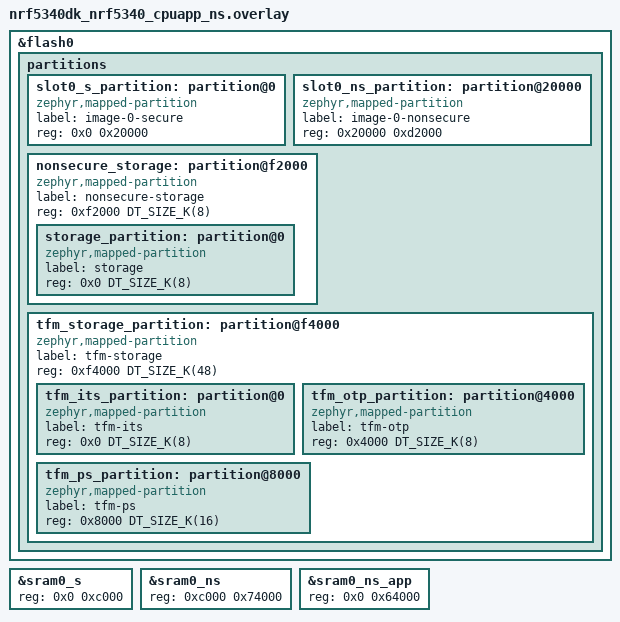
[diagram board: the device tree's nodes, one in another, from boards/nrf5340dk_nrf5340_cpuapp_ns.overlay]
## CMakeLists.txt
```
#
# Copyright (c) 2018 Nordic Semiconductor
#
# SPDX-License-Identifier: LicenseRef-Nordic-5-Clause
#

cmake_minimum_required(VERSION 3.20.0)

find_package(Zephyr REQUIRED HINTS $ENV{ZEPHYR_BASE})
project(NONE)

# NORDIC SDK APP START
if(CONFIG_SOC_NRF9251_CPUAPP)
target_sources(app PRIVATE src/main_cpuapp_idle.c)
else()
target_sources(app PRIVATE src/main.c src/ndef_file_m.c)
endif()
# NORDIC SDK APP END
```

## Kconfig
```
#
# Copyright (c) 2025 Nordic Semiconductor
#
# SPDX-License-Identifier: LicenseRef-Nordic-5-Clause
#

source "Kconfig.zephyr"

config NDEF_FILE_STORAGE_RAM
	bool "Keep NDEF file in RAM only (no flash persistence)"
	default y if RISCV_CORE_NORDIC_VPR
	help
	  Nordic VPR cores (for example nRF9251 CPUPPR/CPUFLPR) cannot use the MRAM
	  flash driver (see SOC_FLASH_NRF_MRAM). Enable this to store the NDEF
	  file in RAM, which is lost on reset.

config ZMS
	select CRC
	default y if (SOC_FLASH_NRF_RRAM || SOC_FLASH_NRF_MRAM) && !NDEF_FILE_STORAGE_RAM

config NVS
	default y if !(SOC_FLASH_NRF_RRAM || SOC_FLASH_NRF_MRAM) && !NDEF_FILE_STORAGE_RAM
```

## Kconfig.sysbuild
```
#
# Copyright (c) 2026 Nordic Semiconductor ASA
#
# SPDX-License-Identifier: LicenseRef-Nordic-5-Clause
#

choice NETCORE
	default NETCORE_EMPTY

endchoice

if SUPPORT_PPRCORE

choice PPRCORE
	default PPRCORE_REMOTE

config PPRCORE_REMOTE
	bool "Remote image (NFC sample on CPUPPR)"

endchoice

config PPRCORE_IMAGE_NAME
	default "remote_ppr" if PPRCORE_REMOTE

config PPRCORE_IMAGE_PATH
	default "$(APP_DIR)/remote" if PPRCORE_REMOTE

endif # SUPPORT_PPRCORE

source "share/sysbuild/Kconfig"
```

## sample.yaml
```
sample:
  description: NFC Writable NDEF Message sample
  name: NFC Writable NDEF Message
tests:
  sample.nfc.writable_ndef_msg:
    sysbuild: true
    build_only: true
    integration_platforms:
      - nrf52840dk/nrf52840
      - nrf5340dk/nrf5340/cpuapp
      - nrf5340dk/nrf5340/cpuapp/ns
      - nrf54h20dk/nrf54h20/cpuapp
      - nrf54l15dk/nrf54l05/cpuapp
      - nrf54l15dk/nrf54l10/cpuapp
      - nrf54l15dk/nrf54l15/cpuapp
      - nrf54lm20dk/nrf54lm20a/cpuapp
      - nrf54lm20dk/nrf54lm20b/cpuapp
      - nrf7120dk/nrf7120/cpuapp
    platform_allow:
      - nrf52840dk/nrf52840
      - nrf52dk/nrf52832
      - nrf5340dk/nrf5340/cpuapp
      - nrf5340dk/nrf5340/cpuapp/ns
      - nrf54h20dk/nrf54h20/cpuapp
      - nrf54l15dk/nrf54l05/cpuapp
      - nrf54l15dk/nrf54l10/cpuapp
      - nrf54l15dk/nrf54l15/cpuapp
      - nrf54lm20dk/nrf54lm20a/cpuapp
      - nrf54lm20dk/nrf54lm20b/cpuapp
      - nrf7120dk/nrf7120/cpuapp
    tags:
      - ci_build
      - sysbuild
      - ci_samples_nfc
  sample.nfc.writable_ndef_msg.llvm:
    toolchain_allow: llvm
    sysbuild: true
    build_only: true
    integration_platforms:
      - nrf54l15dk/nrf54l15/cpuapp
    platform_allow:
      - nrf54l15dk/nrf54l15/cpuapp
    tags:
      - ci_build
      - sysbuild
      - ci_samples_nfc
```

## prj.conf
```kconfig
#
# Copyright (c) 2019 Nordic Semiconductor ASA
#
# SPDX-License-Identifier: LicenseRef-Nordic-5-Clause
#
CONFIG_NCS_SAMPLES_DEFAULTS=y

CONFIG_NFC_T4T_NRFXLIB=y

CONFIG_NFC_NDEF=y
CONFIG_NFC_NDEF_MSG=y
CONFIG_NFC_NDEF_RECORD=y
CONFIG_NFC_NDEF_URI_REC=y
CONFIG_NFC_NDEF_URI_MSG=y

CONFIG_MPU_ALLOW_FLASH_WRITE=y
CONFIG_FLASH=y
CONFIG_FLASH_PAGE_LAYOUT=y
CONFIG_DK_LIBRARY=y
```

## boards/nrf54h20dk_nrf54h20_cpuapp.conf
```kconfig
#
# Copyright (c) 2024 Nordic Semiconductor ASA
#
# SPDX-License-Identifier: LicenseRef-Nordic-5-Clause
#

CONFIG_NVS=n
CONFIG_ZMS=y
```

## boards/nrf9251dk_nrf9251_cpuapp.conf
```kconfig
#
# Copyright (c) 2026 Nordic Semiconductor ASA
#
# SPDX-License-Identifier: LicenseRef-Nordic-5-Clause
#

# Disable NFC low latency IRQ
CONFIG_NFC_LOW_LATENCY_IRQ=n

# Application core stays idle
CONFIG_PM=y
CONFIG_PM_DEVICE=y
CONFIG_PM_DEVICE_RUNTIME=y
CONFIG_POWEROFF=y

CONFIG_NFC_T4T_NRFXLIB=n
CONFIG_NFC_NDEF=n
CONFIG_NFC_NDEF_MSG=n
CONFIG_NFC_NDEF_RECORD=n
CONFIG_NFC_NDEF_URI_REC=n
CONFIG_NFC_NDEF_URI_MSG=n

CONFIG_DK_LIBRARY=n
CONFIG_FLASH=n
CONFIG_FLASH_PAGE_LAYOUT=n
CONFIG_MPU_ALLOW_FLASH_WRITE=n

CONFIG_SERIAL=n
CONFIG_CONSOLE=n
CONFIG_UART_CONSOLE=n
CONFIG_PRINTK=n
CONFIG_LOG=n
CONFIG_BOOT_BANNER=n
CONFIG_NCS_BOOT_BANNER=n
```

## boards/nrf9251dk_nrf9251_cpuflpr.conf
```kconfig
#
# Copyright (c) 2026 Nordic Semiconductor ASA
#
# SPDX-License-Identifier: LicenseRef-Nordic-5-Clause
#

# Disable NFC low latency IRQ
CONFIG_NFC_LOW_LATENCY_IRQ=n

CONFIG_DK_LIBRARY=n

CONFIG_FLASH=n
CONFIG_FLASH_PAGE_LAYOUT=n
CONFIG_MPU_ALLOW_FLASH_WRITE=n

CONFIG_REBOOT=n
CONFIG_ASSERT=n
```

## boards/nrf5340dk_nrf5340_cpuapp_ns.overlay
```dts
/*
 * Copyright (c) 2026 Nordic Semiconductor ASA
 *
 * SPDX-License-Identifier: LicenseRef-Nordic-5-Clause
 */

/delete-node/ &boot_partition;
/delete-node/ &slot0_partition;
/delete-node/ &slot1_partition;
/delete-node/ &tfm_its_partition;
/delete-node/ &tfm_otp_partition;
/delete-node/ &tfm_ps_partition;
/delete-node/ &storage_partition;

&flash0 {
	partitions {
		slot0_s_partition: partition@0 {
			compatible = "zephyr,mapped-partition";
			label = "image-0-secure";
			reg = <0x0 0x20000>;
		};

		slot0_ns_partition: partition@20000 {
			compatible = "zephyr,mapped-partition";
			label = "image-0-nonsecure";
			reg = <0x20000 0xd2000>;
		};

		nonsecure_storage: partition@f2000 {
			compatible = "zephyr,mapped-partition";
			label = "nonsecure-storage";
			reg = <0xf2000 DT_SIZE_K(8)>;
			ranges = <0x0 0xf2000 DT_SIZE_K(8)>;
			#address-cells = <1>;
			#size-cells = <1>;

			storage_partition: partition@0 {
				compatible = "zephyr,mapped-partition";
				label = "storage";
				reg = <0x0 DT_SIZE_K(8)>;
			};
		};

		tfm_storage_partition: partition@f4000 {
			compatible = "zephyr,mapped-partition";
			label = "tfm-storage";
			reg = <0xf4000 DT_SIZE_K(48)>;
			ranges = <0x0 0xf4000 DT_SIZE_K(48)>;
			#address-cells = <1>;
			#size-cells = <1>;

			tfm_its_partition: partition@0 {
				compatible = "zephyr,mapped-partition";
				label = "tfm-its";
				reg = <0x0 DT_SIZE_K(8)>;
			};

			tfm_otp_partition: partition@4000 {
				compatible = "zephyr,mapped-partition";
				label = "tfm-otp";
				reg = <0x4000 DT_SIZE_K(8)>;
			};

			tfm_ps_partition: partition@8000 {
				compatible = "zephyr,mapped-partition";
				label = "tfm-ps";
				reg = <0x8000 DT_SIZE_K(16)>;
			};
		};
	};
};

&sram0_s {
	reg = <0x0 0xc000>;
};

&sram0_ns {
	reg = <0xc000 0x74000>;
	ranges = <0x0 0xc000 0x74000>;
};

&sram0_ns_app {
	reg = <0x0 0x64000>;
};

/*
 * This layout redefines the flash partition map, dropping partitions that the
 * upstream nordic-tz-secure/-nonsecure descriptors reference. Remove the
 * descriptors so they do not hold dangling phandles (restores the behaviour
 * from before the descriptors were introduced).
 */
/ {
	/delete-node/ nordic-tz-secure;
	/delete-node/ nordic-tz-nonsecure;
};
```

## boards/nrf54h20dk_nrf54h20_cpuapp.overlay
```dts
/*
 * Copyright (c) 2024 Nordic Semiconductor ASA
 *
 * SPDX-License-Identifier: LicenseRef-Nordic-5-Clause
 */

&nfct {
	status = "okay";
	memory-regions = <&cpuapp_dma_region>;
};

&timer137 {
	status = "okay";
};
```

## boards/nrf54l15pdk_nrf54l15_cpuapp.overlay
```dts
/*
 * Copyright (c) 2024 Nordic Semiconductor ASA
 *
 * SPDX-License-Identifier: LicenseRef-Nordic-5-Clause
 */

/*
 * The sample does not use Buttons 3 and 4.
 * Buttons 3 and 4 in PDK are connected to the GPIO port, which does not support interrupts.
 */

 / {
	aliases {
		/delete-property/ sw2;
		/delete-property/ sw3;
	};
	buttons {
		/delete-node/ button_2;
		/delete-node/ button_3;
	};
};
```

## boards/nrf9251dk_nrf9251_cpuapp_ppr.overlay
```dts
/*
 * Copyright (c) 2026 Nordic Semiconductor ASA
 *
 * SPDX-License-Identifier: LicenseRef-Nordic-5-Clause
 */

&gpiote130 {
	status = "okay";
};

&cpuppr_vpr {
	status = "okay";
};

&uart132 {
	status = "reserved";
	interrupt-parent = <&cpuppr_clic>;
};

&nfct {
	status = "reserved";
	interrupt-parent = <&cpuppr_clic>;
};

&hfxo {
	status = "reserved";
};
```

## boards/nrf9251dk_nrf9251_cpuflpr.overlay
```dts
/*
 * Copyright (c) 2026 Nordic Semiconductor ASA
 *
 * SPDX-License-Identifier: LicenseRef-Nordic-5-Clause
 */

&nfct {
	status = "okay";
	interrupt-parent = <&cpuflpr_clic>;
};

&hfxo {
	status = "okay";
};

&gpio0 {
	status = "okay";
};

&gpio2 {
	status = "okay";
};

&gpiote130 {
	status = "okay";
};
```

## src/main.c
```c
/*
 * Copyright (c) 2018 Nordic Semiconductor ASA
 *
 * SPDX-License-Identifier: LicenseRef-Nordic-5-Clause
 */

/** @file
 *
 * @defgroup nfc_writable_ndef_msg_example_main main.c
 * @{
 * @ingroup nfc_writable_ndef_msg_example
 * @brief The application main file of NFC writable NDEF message example.
 *
 */

#include <zephyr/kernel.h>
#if defined(CONFIG_REBOOT)
#include <zephyr/sys/reboot.h>
#endif /* CONFIG_REBOOT */

#include "ndef_file_m.h"

#include <nfc_t4t_lib.h>
#include <nfc/ndef/msg.h>
#include <nfc/t4t/ndef_file.h>

#if defined(CONFIG_DK_LIBRARY)
#include <dk_buttons_and_leds.h>

#define NFC_FIELD_LED		DK_LED1
#define NFC_WRITE_LED		DK_LED2
#define NFC_READ_LED		DK_LED4

#define NDEF_RESTORE_BTN_MSK	DK_BTN1_MSK
#endif /* CONFIG_DK_LIBRARY */

static uint8_t ndef_msg_buf[CONFIG_NDEF_FILE_SIZE]; /**< Buffer for NDEF file. */

enum {
	FLASH_WRITE_FINISHED,
	FLASH_BUF_PREP_STARTED,
	FLASH_BUF_PREP_FINISHED,
	FLASH_WRITE_STARTED,
};

static atomic_t op_flags;

static uint8_t flash_buf[CONFIG_NDEF_FILE_SIZE]; /**< Buffer for storage update. */
static uint8_t flash_buf_len; /**< Length of the storage buffer. */

static K_SEM_DEFINE(nfc_write_sem, 0, 1);

static void flash_buffer_prepare(size_t data_length)
{
	if (atomic_cas(&op_flags, FLASH_WRITE_FINISHED,
			FLASH_BUF_PREP_STARTED)) {
		flash_buf_len = data_length + NFC_NDEF_FILE_NLEN_FIELD_SIZE;
		memcpy(flash_buf, ndef_msg_buf, sizeof(flash_buf));

		atomic_set(&op_flags, FLASH_BUF_PREP_FINISHED);
		k_sem_give(&nfc_write_sem);
	} else {
		printk("Flash update pending. Discarding new data...\n");
	}

}

/**
 * @brief Callback function for handling NFC events.
 */
static void nfc_callback(void *context,
			 nfc_t4t_event_t event,
			 const uint8_t *data,
			 size_t data_length,
			 uint32_t flags)
{
	ARG_UNUSED(context);
	ARG_UNUSED(data);
	ARG_UNUSED(flags);

	switch (event) {
	case NFC_T4T_EVENT_FIELD_ON:
#if defined(CONFIG_DK_LIBRARY)
		dk_set_led_on(NFC_FIELD_LED);
#endif /* CONFIG_DK_LIBRARY */
		break;

	case NFC_T4T_EVENT_FIELD_OFF:
#if defined(CONFIG_DK_LIBRARY)
		dk_set_leds(DK_NO_LEDS_MSK);
#endif /* CONFIG_DK_LIBRARY */
		break;

	case NFC_T4T_EVENT_NDEF_READ:
#if defined(CONFIG_DK_LIBRARY)
		dk_set_led_on(NFC_READ_LED);
#endif /* CONFIG_DK_LIBRARY */
		break;

	case NFC_T4T_EVENT_NDEF_UPDATED:
		if (data_length > 0) {
#if defined(CONFIG_DK_LIBRARY)
			dk_set_led_on(NFC_WRITE_LED);
#endif /* CONFIG_DK_LIBRARY */
			flash_buffer_prepare(data_length);
		}
		break;

	default:
		break;
	}
}

static int board_init(void)
{
	int err = 0;

#if defined(CONFIG_DK_LIBRARY)
	err = dk_buttons_init(NULL);
	if (err) {
		printk("Cannot init buttons (err: %d)\n", err);
		return err;
	}

	err = dk_leds_init();
	if (err) {
		printk("Cannot init LEDs (err: %d)\n", err);
	}
#endif /* CONFIG_DK_LIBRARY */

	return err;
}

/**
 * @brief   Function for application main entry.
 */
int main(void)
{
	/* Configure LED-pins as outputs. */
	if (board_init() < 0) {
		printk("Cannot initialize board!\n");
		goto fail;
	}

	/* Initialize storage. */
	if (ndef_file_setup() < 0) {
		printk("Cannot setup NDEF file!\n");
		goto fail;
	}

	/* Load NDEF message. */
	if (ndef_file_load(ndef_msg_buf, sizeof(ndef_msg_buf)) < 0) {
		printk("Cannot load NDEF file!\n");
		goto fail;
	}

#if defined(CONFIG_DK_LIBRARY)
	/* Restore default NDEF message if button is pressed. */
	uint32_t button_state;

	dk_read_buttons(&button_state, NULL);
	if (button_state & NDEF_RESTORE_BTN_MSK) {
		if (ndef_restore_default(ndef_msg_buf,
					 sizeof(ndef_msg_buf)) < 0) {
			printk("Cannot flash NDEF message!\n");
			goto fail;
		}
		printk("Default NDEF message restored!\n");
	}
#endif /* CONFIG_DK_LIBRARY */

	/* Set up NFC */
	int err = nfc_t4t_setup(nfc_callback, NULL);

	if (err < 0) {
		printk("Cannot setup t4t library!\n");
		goto fail;
	}
	/* Run Read-Write mode for Type 4 Tag platform */
	if (nfc_t4t_ndef_rwpayload_set(ndef_msg_buf,
				       sizeof(ndef_msg_buf)) < 0) {
		printk("Cannot set payload!\n");
		goto fail;
	}
	/* Start sensing NFC field */
	if (nfc_t4t_emulation_start() < 0) {
		printk("Cannot start emulation!\n");
		goto fail;
	}
	printk("Starting NFC Writable NDEF Message sample\n");

	while (true) {
		k_sem_take(&nfc_write_sem, K_FOREVER);
		if (atomic_cas(&op_flags, FLASH_BUF_PREP_FINISHED,
				FLASH_WRITE_STARTED)) {
			if (ndef_file_update(flash_buf, flash_buf_len) < 0) {
				printk("Cannot update NDEF message!\n");
			} else {
				printk("NDEF message successfully updated.\n");
			}
			atomic_set(&op_flags, FLASH_WRITE_FINISHED);
		}
	}

fail:
#if defined(CONFIG_REBOOT)
	sys_reboot(SYS_REBOOT_COLD);
#endif /* CONFIG_REBOOT */
	return -EIO;
}
/** @} */
```

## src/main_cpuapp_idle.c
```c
/*
 * Copyright (c) 2026 Nordic Semiconductor ASA
 *
 * SPDX-License-Identifier: LicenseRef-Nordic-5-Clause
 */

/** @file
 * @brief Idle application core main for nRF9251 sysbuild (NFC runs on CPUPPR).
 */

#include <zephyr/kernel.h>
#include <zephyr/logging/log.h>

LOG_MODULE_REGISTER(writable_ndef_msg, LOG_LEVEL_INF);

int main(void)
{
	LOG_INF("Application core idle. The NFC Writable NDEF sample runs on CPUPPR");

	while (true) {
		k_sleep(K_FOREVER);
	}

	return 0;
}
```

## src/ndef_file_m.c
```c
/*
 * Copyright (c) 2018 Nordic Semiconductor ASA
 *
 * SPDX-License-Identifier: LicenseRef-Nordic-5-Clause
 */

/** @file
 *
 * @ingroup nfc_writable_ndef_msg_example_ndef_file_m ndef_file_m.c
 * @{
 * @ingroup nfc_writable_ndef_msg_example
 * @brief FLASH service for the NFC writable NDEF message example.
 *
 */

#include <zephyr/kernel.h>
#include <soc.h>
#include <zephyr/device.h>
#include <nfc/t4t/ndef_file.h>
#include <nfc/ndef/uri_msg.h>
#include "ndef_file_m.h"

#if !defined(CONFIG_NDEF_FILE_STORAGE_RAM)
#include <zephyr/storage/flash_map.h>
#endif /* !defined(CONFIG_NDEF_FILE_STORAGE_RAM) */
#if defined(CONFIG_NVS)
#include <zephyr/kvss/nvs.h>
#elif defined(CONFIG_ZMS)
#include <zephyr/kvss/zms.h>
#endif /* defined(CONFIG_NVS) */

#define FLASH_URL_ADDRESS_ID 1 /**< Address of URL message in FLASH */

static const uint8_t m_url[] = /**< Default NDEF message: URL "nordicsemi.com". */
	{'n', 'o', 'r', 'd', 'i', 'c', 's', 'e', 'm', 'i', '.', 'c', 'o', 'm'};

#if defined(CONFIG_NDEF_FILE_STORAGE_RAM)

static uint8_t ram_ndef[CONFIG_NDEF_FILE_SIZE];
static uint32_t ram_ndef_len;
static bool ram_ndef_valid;

#else /* CONFIG_NDEF_FILE_STORAGE_RAM */

/* Flash partition for storage*/
#define FLASH_DEVICE PARTITION_DEVICE(storage_partition)
/* Flash block size in bytes */
#define SECTOR_SIZE  (DT_PROP(DT_CHOSEN(zephyr_flash), erase_block_size))
#define SECTOR_COUNT 2
/* Start address of the filesystem in flash */
#define STORAGE_OFFSET PARTITION_OFFSET(storage_partition)

#if defined(CONFIG_NVS)
static struct nvs_fs fs = {
	.sector_size = SECTOR_SIZE,
	.sector_count = SECTOR_COUNT,
	.offset = STORAGE_OFFSET,
};
#elif defined(CONFIG_ZMS)
static struct zms_fs fs = {
	.sector_size = SECTOR_SIZE,
	.sector_count = SECTOR_COUNT,
	.offset = STORAGE_OFFSET,
};
#else
#error "Please select file system."
#endif /* defined(CONFIG_NVS) */

#endif /* CONFIG_NDEF_FILE_STORAGE_RAM */

int ndef_file_setup(void)
{
#if defined(CONFIG_NDEF_FILE_STORAGE_RAM)
	return 0;
#else /* CONFIG_NDEF_FILE_STORAGE_RAM */
	int err = 0;

	fs.flash_device = FLASH_DEVICE;
	if (fs.flash_device == NULL) {
		return -ENODEV;
	}

#if defined(CONFIG_NVS)
	err = nvs_mount(&fs);
#elif defined(CONFIG_ZMS)
	err = zms_mount(&fs);
#endif /* defined(CONFIG_NVS) */

	if (err < 0) {
		printk("Cannot initialize storage!\n");
	}

	return err;
#endif /* CONFIG_NDEF_FILE_STORAGE_RAM */
}

int ndef_file_update(uint8_t const *buff, uint32_t size)
{
	/* Update storage with new NDEF message. */
#if defined(CONFIG_NVS)
	return nvs_write(&fs, FLASH_URL_ADDRESS_ID, buff, size);
#elif defined(CONFIG_ZMS)
	return zms_write(&fs, FLASH_URL_ADDRESS_ID, buff, size);
#elif defined(CONFIG_NDEF_FILE_STORAGE_RAM)
	if (size > CONFIG_NDEF_FILE_SIZE) {
		return -ENOMEM;
	}

	memcpy(ram_ndef, buff, size);
	ram_ndef_len = size;
	ram_ndef_valid = true;

	return size;
#endif /* defined(CONFIG_NVS) */
}

/** .. include_startingpoint_ndef_file_rst */
int ndef_file_default_message(uint8_t *buff, uint32_t *size)
{
	int err;
	uint32_t ndef_size = nfc_t4t_ndef_file_msg_size_get(*size);

	/* Encode URI message into buffer. */
	err = nfc_ndef_uri_msg_encode(NFC_URI_HTTP_WWW,
				      m_url,
				      sizeof(m_url),
				      nfc_t4t_ndef_file_msg_get(buff),
				      &ndef_size);
	if (err) {
		return err;
	}

	err = nfc_t4t_ndef_file_encode(buff, &ndef_size);
	if (err) {
		return err;
	}

	*size = ndef_size;

	return 0;
}
/** .. include_endpoint_ndef_file_rst */

int ndef_restore_default(uint8_t *buff, uint32_t size)
{
	int err;

	err = ndef_file_default_message(buff, &size);
	if (err < 0) {
		printk("Cannot create default message!\n");
		return err;
	}

	/* Save record with default NDEF message. */
	err = ndef_file_update(buff, size);
	if (err < 0) {
		printk("Cannot flash NDEF message!\n");
	}
	return err;
}

int ndef_file_load(uint8_t *buff, uint32_t size)
{
#if defined(CONFIG_NDEF_FILE_STORAGE_RAM)
	if (ram_ndef_valid && ram_ndef_len <= size) {
		memcpy(buff, ram_ndef, ram_ndef_len);
		printk("Found NDEF file in RAM.\n");
		return ram_ndef_len;
	}

	printk("NDEF file not in RAM, creating default NDEF.\n");
	return ndef_restore_default(buff, size);
#else /* CONFIG_NDEF_FILE_STORAGE_RAM */
	int err = 0;

	/* If there is no record with given ID, create default message and store
	 * in FLASH. FLASH_URL_ADDRESS_ID is used to store an address, lets see
	 * if we can read it from flash, since we don't know the size read the
	 * maximum possible
	 */
#if defined(CONFIG_NVS)
	err = nvs_read(&fs, FLASH_URL_ADDRESS_ID, buff, size);
#elif defined(CONFIG_ZMS)
	err = zms_read(&fs, FLASH_URL_ADDRESS_ID, buff, size);
#endif /* defined(CONFIG_NVS) */

	if (err > 0) { /* Item was found, show it */
		printk("Found NDEF file record.\n");
	} else {
		printk("NDEF file record not found, creating default NDEF.\n");
		/* Create default NDEF message. */
		err = ndef_restore_default(buff, size);
	}

	return err;
#endif /* CONFIG_NDEF_FILE_STORAGE_RAM */
}

/** @} */
```

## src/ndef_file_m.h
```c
/*
 * Copyright (c) 2018 Nordic Semiconductor ASA
 *
 * SPDX-License-Identifier: LicenseRef-Nordic-5-Clause
 */

#ifndef _NDEF_FILE_M_H__
#define _NDEF_FILE_M_H__

/** @file
 *
 * @defgroup nfc_writable_ndef_msg_example_ndef_file_m ndef_file_m.h
 * @{
 * @ingroup nfc_writable_ndef_msg_example
 * @brief FLASH service for the NFC writable NDEF message example.
 *
 */

#include <zephyr/types.h>

/**
 * @brief   Function for initializing the storage module.
 *
 * @return 0 when module has been set up properly,
 * error code otherwise.
 */
int ndef_file_setup(void);

/**
 * @brief   Function for updating NDEF message in the flash file.
 *
 * @details Storage update operation is performed on main loop.
 *
 * @param buff Pointer to the NDEF message to be stored in flash.
 * @param size Size of NDEF message.
 *
 * @return  0 when update request has been added to the queue.
 *          Otherwise, error code.
 */
int ndef_file_update(uint8_t const *buff, uint32_t size);

/**
 * @brief Function for loading NDEF message from the flash file.
 *
 * @details If the record does not exist, the default NDEF message
 * is created and stored in flash.
 *
 * @param buff Pointer to the buffer for NDEF message.
 * @param size Size of the buffer.
 *
 * @return  0 when NDEF message has been retrieved properly. Otherwise error
 * code is returned.
 */
int ndef_file_load(uint8_t *buff, uint32_t size);

/**
 * @brief Function for creating the default NDEF message: URL "nordicsemi.com".
 *
 * @param buff Pointer to the NDEF message buffer.
 * @param size Pointer to the variable holding buffer size as input, size
 * of the created message as output.
 *
 * @return 0 if the message has been created, error code otherwise.
 */
int ndef_file_default_message(uint8_t *buff, uint32_t *size);

/**
 * @brief Function for creating and storing the default NDEF message:
 * URL "nordicsemi.com".
 *
 * @param buff Pointer to the NDEF message buffer.
 * @param size Pointer to the variable holding buffer size as input, size
 * of the created message as output.
 *
 * @return 0 if the message has been created, error code otherwise.
 */
int ndef_restore_default(uint8_t *buff, uint32_t size);

/** @} */

#endif /* _NDEF_FILE_M_H__ */
```
